AUTOSAR XML (schema 4-2-1)
package /ComponentTypes
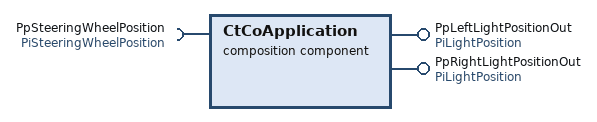
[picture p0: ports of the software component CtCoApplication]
  composition sw component type CtCoApplication
    provide port PpLeftLightPositionOut: provided-com-specs=[{data-element=DeLightLength, init-value=0}, {data-element=DeLightPosition, init-value=0}], provided-interface=PiLightPosition
    provide port PpRightLightPositionOut: provided-com-specs=[{data-element=DeLightLength, init-value=0}, {data-element=DeLightPosition, init-value=0}], provided-interface=PiLightPosition
    require port PpSteeringWheelPosition: nonqueued-receiver-com-spec{data-element=DeSteeringWheelPosition, filter=data-filter-type=ALWAYS, init-value=constant-reference=CSteeringWheelInitPosition}, required-interface=PiSteeringWheelPosition
    5 x component:
      CpApAFSController: type=CtApAFSController
      CpCddIoHwAb: type=CtCddIoHwAb
      CpSaLeftFrontlight: type=CtSaFrontlight
      CpSaRightFrontlight: type=CtSaFrontlight
      CpSaSteeringWheel: type=CtSaSteeringWheel
    connect CpApAFSController.PpLightPositionLeft -> CpSaLeftFrontlight.PpLightPositionIn
    connect CpApAFSController.PpLightPositionRight -> CpSaRightFrontlight.PpLightPositionIn
    connect CpCddIoHwAb.PpAFSSwitch -> CpApAFSController.PpAFSSwitch
    connect CpCddIoHwAb.PpHighBeam -> CpApAFSController.PpHighBeam
    connect CpSaSteeringWheel.PpSteeringWheelPositionOut -> CpApAFSController.PpSteeringWheelPosition
    delegate CpSaLeftFrontlight.PpLightPositionOut <-> outer port PpLeftLightPositionOut
    delegate CpSaRightFrontlight.PpLightPositionOut <-> outer port PpRightLightPositionOut
    delegate CpSaSteeringWheel.PpSteeringWheelPositionIn <-> outer port PpSteeringWheelPosition
